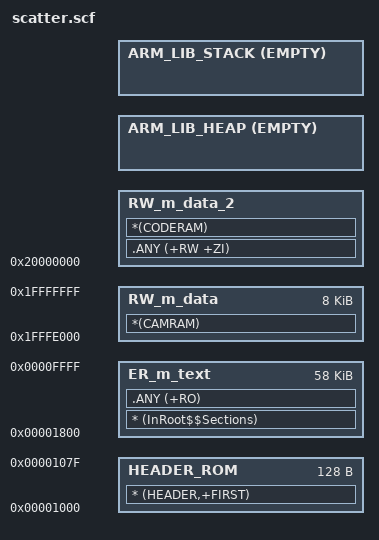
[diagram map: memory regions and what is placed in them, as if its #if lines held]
#! armcc -E

#if (defined(__ram_vector_table__))
  #define __ram_vector_table_size__    0x00000400
#else
  #define __ram_vector_table_size__    0x00001000
#endif

#define m_header_start                 0x00001000
#define m_header_size                  0x00000080

#define m_interrupts_start             0x00001400
#define m_interrupts_size              0x00000400

#define m_text_start                   (m_interrupts_start + m_interrupts_size)
#define m_text_size                    (0x10000 - m_text_start)

#define m_data_start                   0x1FFFE000
#define m_data_size                    0x00002000

#define m_data_2_start                 0x20000000
#define m_data_2_size                  0x00001FF0

/* Sizes */
#if (defined(__stack_size__))
  #define Stack_Size                   __stack_size__
#else
  #define Stack_Size                   0x0400
#endif

#if (defined(__stack_size__))
  #define Heap_Size                    __heap_size__
#else
  #define Heap_Size                    0x0400
#endif

LR_m_text m_text_start m_text_size {   ; load region size_region
  ER_m_text m_text_start m_text_size { ; load address = execution address
    * (InRoot$$Sections)
    .ANY (+RO)
  }
  RW_m_data m_data_start m_data_size { ; RW data
    *(CAMRAM)
  }
  RW_m_data_2 m_data_2_start m_data_2_size-Stack_Size-Heap_Size { ; RW data
    .ANY (+RW +ZI)
    *(CODERAM)
  }
  ARM_LIB_HEAP ((ImageLimit(RW_m_data_2) == m_data_2_start) ? ImageLimit(RW_m_data) : +0) EMPTY Heap_Size { ; Heap region growing up
  }
  ARM_LIB_STACK m_data_2_start+m_data_2_size EMPTY -Stack_Size { ; Stack region growing down
  }
}

LR_m_header m_header_start m_header_size {
  HEADER_ROM m_header_start m_header_size {
    * (HEADER,+FIRST)
  }
}
